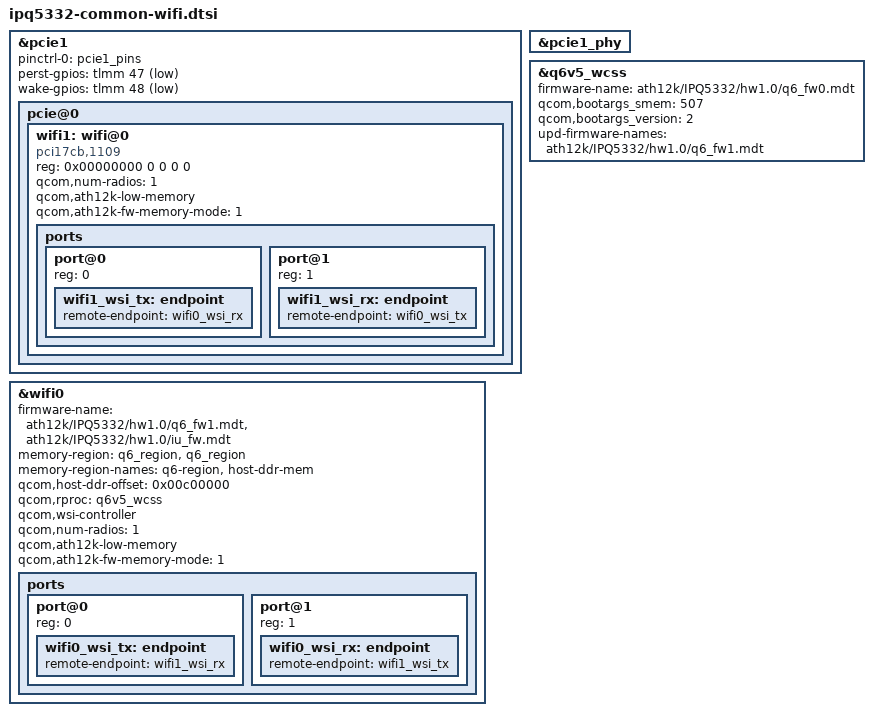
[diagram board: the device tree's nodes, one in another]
// SPDX-License-Identifier: (GPL-2.0+ OR BSD-3-Clause)

/* Keep the fixed UserPD host-DDR address at 0x4b500000 as a view into
 * Q6. M3, CALDB and the group's shared MLO pool are allocated on demand.
 */

&pcie1 {
	status = "okay";

	pinctrl-0 = <&pcie1_pins>;
	pinctrl-names = "default";

	perst-gpios = <&tlmm 47 GPIO_ACTIVE_LOW>;
	wake-gpios = <&tlmm 48 GPIO_ACTIVE_LOW>;

	pcie@0 {
		wifi1: wifi@0 {
			compatible = "pci17cb,1109";
			reg = <0x00000000 0 0 0 0>;
			qcom,num-radios = <1>;
			qcom,ath12k-low-memory;
			qcom,ath12k-fw-memory-mode = <1>;

			ports {
				#address-cells = <1>;
				#size-cells = <0>;

				port@0 {
					reg = <0>;

					wifi1_wsi_tx: endpoint {
						remote-endpoint = <&wifi0_wsi_rx>;
					};
				};

				port@1 {
					reg = <1>;

					wifi1_wsi_rx: endpoint {
						remote-endpoint = <&wifi0_wsi_tx>;
					};
				};
			};
		};
	};
};

&pcie1_phy {
	status = "okay";
};

&q6v5_wcss {
	status = "okay";

	firmware-name = "ath12k/IPQ5332/hw1.0/q6_fw0.mdt";
	qcom,bootargs_smem = <507>;
	qcom,bootargs_version = <2>;
	upd-firmware-names = "ath12k/IPQ5332/hw1.0/q6_fw1.mdt";
};

&wifi0 {
	status = "okay";

	firmware-name = "ath12k/IPQ5332/hw1.0/q6_fw1.mdt", "ath12k/IPQ5332/hw1.0/iu_fw.mdt";
	memory-region = <&q6_region>, <&q6_region>;
	memory-region-names = "q6-region", "host-ddr-mem";
	qcom,host-ddr-offset = <0x00c00000>;
	qcom,rproc = <&q6v5_wcss>;
	qcom,wsi-controller;
	qcom,num-radios = <1>;
	qcom,ath12k-low-memory;
	qcom,ath12k-fw-memory-mode = <1>;

	ports {
		#address-cells = <1>;
		#size-cells = <0>;

		port@0 {
			reg = <0>;

			wifi0_wsi_tx: endpoint {
				remote-endpoint = <&wifi1_wsi_rx>;
			};
		};

		port@1 {
			reg = <1>;

			wifi0_wsi_rx: endpoint {
				remote-endpoint = <&wifi1_wsi_tx>;
			};
		};
	};
};
